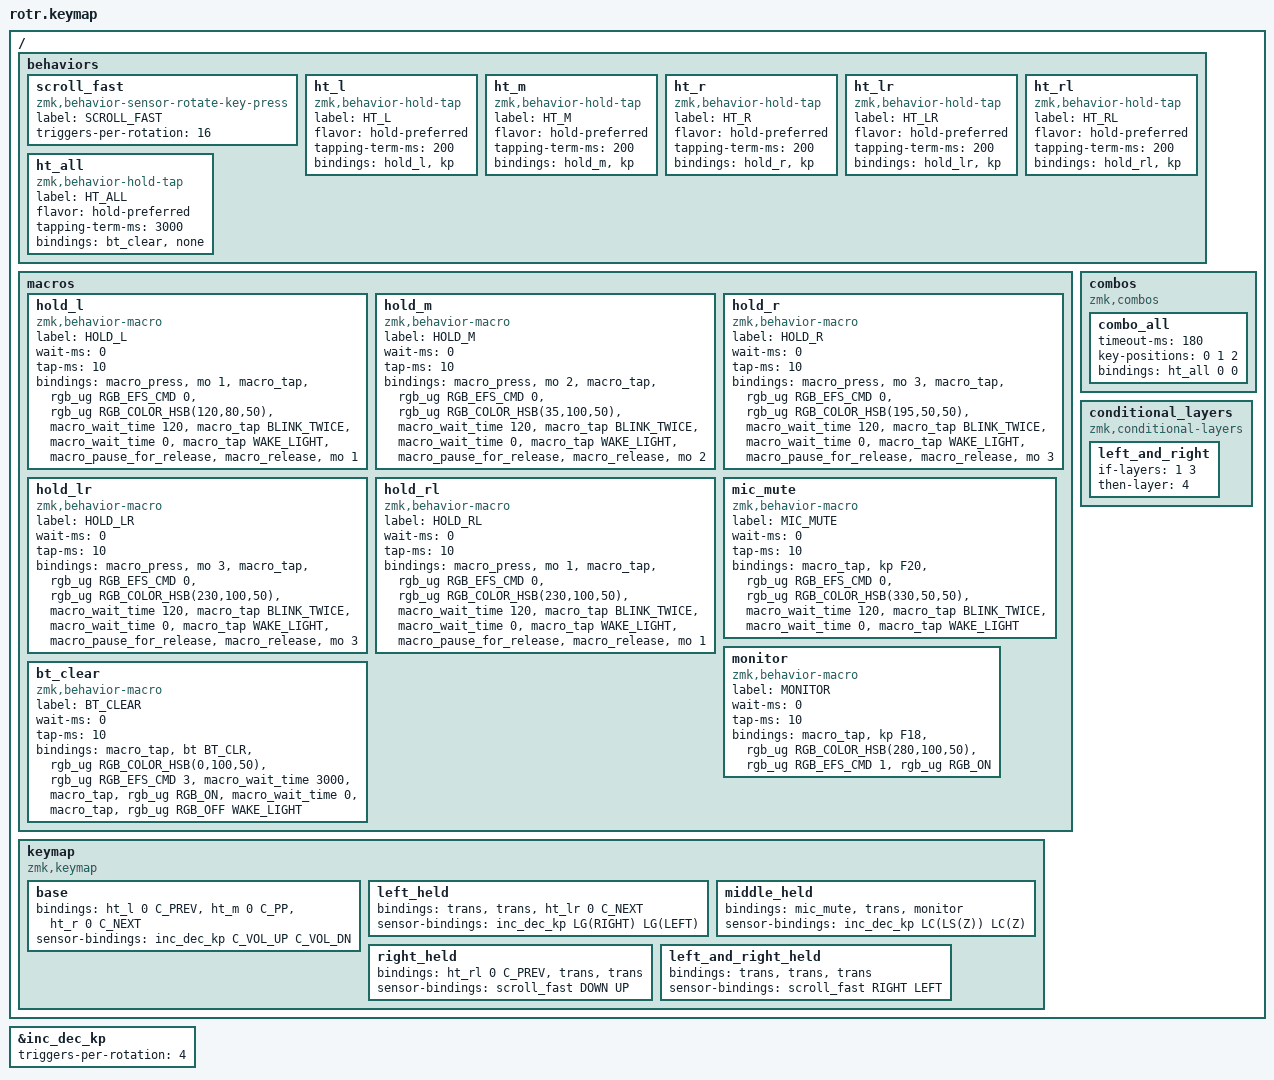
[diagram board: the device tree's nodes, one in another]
/*
 * The ROTR's layout, from keyboard's PLAN-chapter2.md (design table, amended 2026-10-01).
 *
 * Tap: previous track | play-pause | next track. Wheel alone: volume.
 * Hold a key about 0.2 s, then turn the wheel:
 *   left           step through PaperWM windows (Super+Left/Right), two green blinks
 *   middle         undo and redo, two amber blinks
 *   right          vertical scroll with arrows, 16 a turn, two light-blue blinks
 *   left and right horizontal scroll with arrows, 16 a turn, two dark-blue blinks
 * Hold middle, tap left: microphone mute (F20), two pink blinks.
 * Hold middle, tap right: monitor off and on (F18), one purple fade.
 * Hold all three for 3 s: clear the Bluetooth pairing, rainbow for 3 s.
 *
 * Lights: with nothing held, any touch after 2 s of rest shows a white fade, gone 2 to 3 s after
 * the last touch (CONFIG_ZMK_IDLE_TIMEOUT in rotr_defconfig). Every routine ends by putting that
 * white fade back while the lights are off. No routine keeps a long wait in the shared macro
 * queue, because a wait there holds up every key release behind it; the rainbow is the one
 * exception.
 */
#include <behaviors.dtsi>
#include <dt-bindings/zmk/keys.h>
#include <dt-bindings/zmk/rgb.h>
#include <dt-bindings/zmk/bt.h>

/*
 * The resting light: white breathe at speed 2. Colour first, then the effect, which saves both.
 * Speed can only be stepped and stops at 1, so four steps down and one up always land on 2.
 */
#define WAKE_LIGHT &rgb_ug RGB_COLOR_HSB(0,0,50) &rgb_ug RGB_EFS_CMD 1 \
	&rgb_ug RGB_SPD &rgb_ug RGB_SPD &rgb_ug RGB_SPD &rgb_ug RGB_SPD &rgb_ug RGB_SPI

#define BLINK_TWICE &rgb_ug RGB_ON &rgb_ug RGB_OFF &rgb_ug RGB_ON &rgb_ug RGB_OFF

&inc_dec_kp {
	triggers-per-rotation = <4>;
};

/ {
	behaviors {
		scroll_fast: scroll_fast {
			compatible = "zmk,behavior-sensor-rotate-key-press";
			label = "SCROLL_FAST";
			#sensor-binding-cells = <2>;
			triggers-per-rotation = <16>;
		};
		ht_l: ht_l {
			compatible = "zmk,behavior-hold-tap";
			label = "HT_L";
			#binding-cells = <2>;
			flavor = "hold-preferred";
			tapping-term-ms = <200>;
			bindings = <&hold_l>, <&kp>;
		};
		ht_m: ht_m {
			compatible = "zmk,behavior-hold-tap";
			label = "HT_M";
			#binding-cells = <2>;
			flavor = "hold-preferred";
			tapping-term-ms = <200>;
			bindings = <&hold_m>, <&kp>;
		};
		ht_r: ht_r {
			compatible = "zmk,behavior-hold-tap";
			label = "HT_R";
			#binding-cells = <2>;
			flavor = "hold-preferred";
			tapping-term-ms = <200>;
			bindings = <&hold_r>, <&kp>;
		};
		// right held while left is held: dark-blue blinks, then layers 1 and 3 make layer 4
		ht_lr: ht_lr {
			compatible = "zmk,behavior-hold-tap";
			label = "HT_LR";
			#binding-cells = <2>;
			flavor = "hold-preferred";
			tapping-term-ms = <200>;
			bindings = <&hold_lr>, <&kp>;
		};
		// left held while right is held: the same, in the other order
		ht_rl: ht_rl {
			compatible = "zmk,behavior-hold-tap";
			label = "HT_RL";
			#binding-cells = <2>;
			flavor = "hold-preferred";
			tapping-term-ms = <200>;
			bindings = <&hold_rl>, <&kp>;
		};
		ht_all: ht_all {
			compatible = "zmk,behavior-hold-tap";
			label = "HT_ALL";
			#binding-cells = <2>;
			flavor = "hold-preferred";
			tapping-term-ms = <3000>;
			bindings = <&bt_clear>, <&none>;
		};
	};

	macros {
		hold_l: hold_l {
			compatible = "zmk,behavior-macro";
			label = "HOLD_L";
			#binding-cells = <0>;
			wait-ms = <0>;
			tap-ms = <10>;
			bindings
				= <&macro_press &mo 1>
				, <&macro_tap &rgb_ug RGB_EFS_CMD 0 &rgb_ug RGB_COLOR_HSB(120,80,50)>
				, <&macro_wait_time 120>
				, <&macro_tap BLINK_TWICE>
				, <&macro_wait_time 0>
				, <&macro_tap WAKE_LIGHT>
				, <&macro_pause_for_release>
				, <&macro_release &mo 1>
				;
		};
		hold_m: hold_m {
			compatible = "zmk,behavior-macro";
			label = "HOLD_M";
			#binding-cells = <0>;
			wait-ms = <0>;
			tap-ms = <10>;
			bindings
				= <&macro_press &mo 2>
				, <&macro_tap &rgb_ug RGB_EFS_CMD 0 &rgb_ug RGB_COLOR_HSB(35,100,50)>
				, <&macro_wait_time 120>
				, <&macro_tap BLINK_TWICE>
				, <&macro_wait_time 0>
				, <&macro_tap WAKE_LIGHT>
				, <&macro_pause_for_release>
				, <&macro_release &mo 2>
				;
		};
		hold_r: hold_r {
			compatible = "zmk,behavior-macro";
			label = "HOLD_R";
			#binding-cells = <0>;
			wait-ms = <0>;
			tap-ms = <10>;
			bindings
				= <&macro_press &mo 3>
				, <&macro_tap &rgb_ug RGB_EFS_CMD 0 &rgb_ug RGB_COLOR_HSB(195,50,50)>
				, <&macro_wait_time 120>
				, <&macro_tap BLINK_TWICE>
				, <&macro_wait_time 0>
				, <&macro_tap WAKE_LIGHT>
				, <&macro_pause_for_release>
				, <&macro_release &mo 3>
				;
		};
		hold_lr: hold_lr {
			compatible = "zmk,behavior-macro";
			label = "HOLD_LR";
			#binding-cells = <0>;
			wait-ms = <0>;
			tap-ms = <10>;
			bindings
				= <&macro_press &mo 3>
				, <&macro_tap &rgb_ug RGB_EFS_CMD 0 &rgb_ug RGB_COLOR_HSB(230,100,50)>
				, <&macro_wait_time 120>
				, <&macro_tap BLINK_TWICE>
				, <&macro_wait_time 0>
				, <&macro_tap WAKE_LIGHT>
				, <&macro_pause_for_release>
				, <&macro_release &mo 3>
				;
		};
		hold_rl: hold_rl {
			compatible = "zmk,behavior-macro";
			label = "HOLD_RL";
			#binding-cells = <0>;
			wait-ms = <0>;
			tap-ms = <10>;
			bindings
				= <&macro_press &mo 1>
				, <&macro_tap &rgb_ug RGB_EFS_CMD 0 &rgb_ug RGB_COLOR_HSB(230,100,50)>
				, <&macro_wait_time 120>
				, <&macro_tap BLINK_TWICE>
				, <&macro_wait_time 0>
				, <&macro_tap WAKE_LIGHT>
				, <&macro_pause_for_release>
				, <&macro_release &mo 1>
				;
		};
		mic_mute: mic_mute {
			compatible = "zmk,behavior-macro";
			label = "MIC_MUTE";
			#binding-cells = <0>;
			wait-ms = <0>;
			tap-ms = <10>;
			bindings
				= <&macro_tap &kp F20 &rgb_ug RGB_EFS_CMD 0 &rgb_ug RGB_COLOR_HSB(330,50,50)>
				, <&macro_wait_time 120>
				, <&macro_tap BLINK_TWICE>
				, <&macro_wait_time 0>
				, <&macro_tap WAKE_LIGHT>
				;
		};
		// The purple fade is left on for the idle timer to switch off: no wait in the queue.
		// Nothing puts the white back here, so the next wake is purple until the next hold.
		monitor: monitor {
			compatible = "zmk,behavior-macro";
			label = "MONITOR";
			#binding-cells = <0>;
			wait-ms = <0>;
			tap-ms = <10>;
			bindings
				= <&macro_tap &kp F18 &rgb_ug RGB_COLOR_HSB(280,100,50) &rgb_ug RGB_EFS_CMD 1 &rgb_ug RGB_ON>
				;
		};
		// A wait sets the gap after the step that follows it, so the 3 s sits after "on".
		// Swirl takes saturation and brightness from the colour, hence the full-saturation red.
		bt_clear: bt_clear {
			compatible = "zmk,behavior-macro";
			label = "BT_CLEAR";
			#binding-cells = <0>;
			wait-ms = <0>;
			tap-ms = <10>;
			bindings
				= <&macro_tap &bt BT_CLR &rgb_ug RGB_COLOR_HSB(0,100,50) &rgb_ug RGB_EFS_CMD 3>
				, <&macro_wait_time 3000>
				, <&macro_tap &rgb_ug RGB_ON>
				, <&macro_wait_time 0>
				, <&macro_tap &rgb_ug RGB_OFF WAKE_LIGHT>
				;
		};
	};

	combos {
		compatible = "zmk,combos";
		// 180 ms, not 100: with middle down first, a third key landing after the window
		// was read on middle's layer, as microphone mute and monitor. It has to stay
		// under the 200 ms that decides a hold.
		combo_all {
			timeout-ms = <180>;
			key-positions = <0 1 2>;
			bindings = <&ht_all 0 0>;
		};
	};

	conditional_layers {
		compatible = "zmk,conditional-layers";
		left_and_right {
			if-layers = <1 3>;
			then-layer = <4>;
		};
	};

	// Wheel bindings are clockwise first.
	keymap {
		compatible = "zmk,keymap";

		base {
			bindings = <&ht_l 0 C_PREV &ht_m 0 C_PP &ht_r 0 C_NEXT>;
			sensor-bindings = <&inc_dec_kp C_VOL_UP C_VOL_DN>;
		};
		left_held {
			bindings = <&trans &trans &ht_lr 0 C_NEXT>;
			sensor-bindings = <&inc_dec_kp LG(RIGHT) LG(LEFT)>;
		};
		middle_held {
			bindings = <&mic_mute &trans &monitor>;
			sensor-bindings = <&inc_dec_kp LC(LS(Z)) LC(Z)>;
		};
		right_held {
			bindings = <&ht_rl 0 C_PREV &trans &trans>;
			sensor-bindings = <&scroll_fast DOWN UP>;
		};
		left_and_right_held {
			bindings = <&trans &trans &trans>;
			sensor-bindings = <&scroll_fast RIGHT LEFT>;
		};
	};
};
